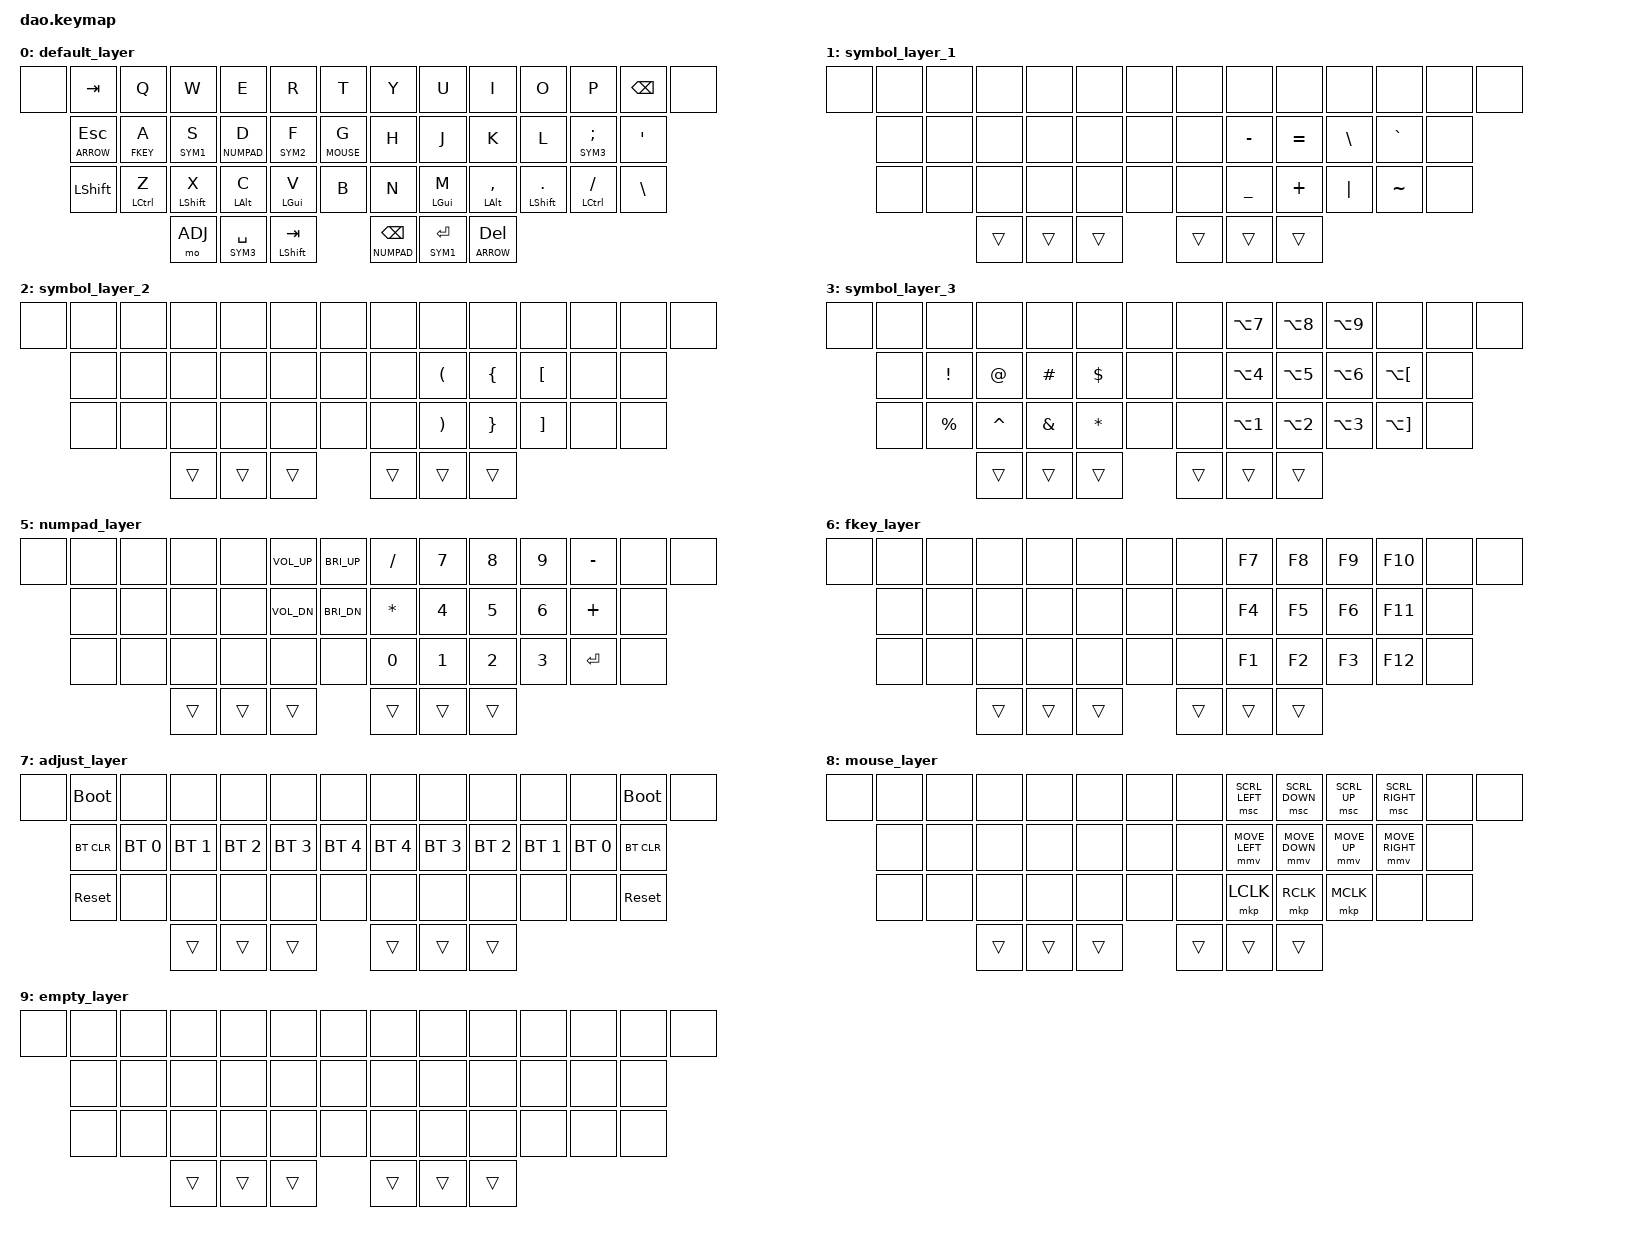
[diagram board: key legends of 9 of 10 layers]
// compile and flash instructions:
// 1. edit this file, push to github,
// 2. download the built files from github actions
// 3. put keyboard into flash mode by double clicking the reset button
// 4. copy them to your keyboard's firmware folder
// note: you have to flash the left one even if you only want to change the right one

/*
 * Copyright (c) 2021 Rafael Yumagulov
 *
 * SPDX-License-Identifier: MIT
 */

#include <behaviors.dtsi>
#include <dt-bindings/zmk/keys.h>
#include <dt-bindings/zmk/bt.h>
#include <dt-bindings/zmk/pointing.h>

// change mouse sensitivity
// #define ZMK_POINTING_DEFAULT_MOVE_VAL 1500  // default: 600
// #define ZMK_POINTING_DEFAULT_SCRL_VAL 20    // default: 10

#define DEF    0
#define SYM1   1
#define SYM2   2
#define SYM3   3
#define ARROW  4
#define NUMPAD 5
#define FKEY   6
#define ADJ    7
#define MOUSE  8

&lt { quick_tap_ms = <200>; };
&mt { quick_tap_ms = <200>; };

/ {
    chosen {
        // zmk,matrix_transform = &default_transform;
        zmk,matrix_transform = &extra_keys_transform;
    };
};

/ {
        behaviors {
                hm: homerow_mods {
                        compatible = "zmk,behavior-hold-tap";
                        label = "HOMEROW_MODS";
                        #binding-cells = <2>;
                        tapping-term-ms = <200>;
                        quick-tap-ms = <200>;
                        flavor = "tap-preferred";
                        bindings = <&kp>, <&kp>;
                };
        };

        keymap {
                compatible = "zmk,keymap";

                default_layer {
                        bindings = <
  &none   &kp TAB           &kp Q         &kp W          &kp E              &kp R                  &kp T         &kp Y                &kp U                 &kp I              &kp O            &kp P            &kp BSPC        &none
          &lt ARROW ESC     &lt FKEY A    &lt SYM1 S     &lt NUMPAD D       &lt SYM2 F             &lt MOUSE G   &kp H                &kp J                 &kp K              &kp L            &lt SYM3 SEMI    &kp SQT
          &kp LSHIFT        &hm LCTRL Z   &hm LSHIFT X   &hm LALT C         &hm LGUI V             &kp B         &kp N                &hm LGUI M            &hm LALT COMMA     &hm LSHIFT DOT   &hm LCTRL FSLH   &kp BSLH
                                          &mo ADJ        &lt SYM3 SPACE     &mt LSHIFT TAB                       &lt NUMPAD BSPC      &lt SYM1 RET          &lt ARROW DEL
                        >;
                };
                symbol_layer_1 {
                        bindings = <
  &none   &none        &none          &none          &none          &none          &none          &none          &none          &none          &none          &none          &none   &none
          &none        &none          &none          &none          &none          &none          &none          &kp MINUS      &kp EQUAL      &kp BSLH       &kp GRAVE      &none
          &none        &none          &none          &none          &none          &none          &none          &kp UNDER      &kp PLUS       &kp PIPE       &kp TILDE      &none
                                                     &trans         &trans         &trans         &trans         &trans         &trans
                        >;
                };
                symbol_layer_2 {
                        bindings = <
  &none   &none        &none          &none          &none          &none          &none          &none          &none          &none          &none          &none          &none   &none
          &none        &none          &none          &none          &none          &none          &none          &kp LPAR       &kp LBRC       &kp LBKT       &none          &none
          &none        &none          &none          &none          &none          &none          &none          &kp RPAR       &kp RBRC       &kp RBKT       &none          &none
                                                     &trans         &trans         &trans         &trans         &trans         &trans
                        >;
                };
                symbol_layer_3 {
                        bindings = <
  &none   &none        &none          &none          &none          &none          &none          &none          &kp LA(N7)      &kp LA(N8)      &kp LA(N9)      &none          &none   &none
          &none        &kp EXCL       &kp AT         &kp HASH       &kp DLLR       &none          &none          &kp LA(N4)      &kp LA(N5)      &kp LA(N6)      &kp LA(LBKT)   &none
          &none        &kp PRCNT      &kp CARET      &kp AMPS       &kp STAR       &none          &none          &kp LA(N1)      &kp LA(N2)      &kp LA(N3)      &kp LA(RBKT)   &none
                                                     &trans         &trans         &trans         &trans         &trans         &trans
                        >;
                };
                arrow_layer {
                        bindings = <
  &none   &none        &none          &none          &kp LC(LS(TAB)) &kp LC(TAB)    &none          &none          &kp BSPC       &kp DEL        &none          &kp PG_UP      &kp HOME   &none
          &none        &none          &kp LA(LEFT)   &kp LA(RIGHT)   &none          &none          &kp LEFT       &kp DOWN       &kp UP         &kp RIGHT      &kp PG_DN      &kp END
          &none        &none          &kp LG(LBKT)   &kp LG(RBKT)    &none          &none          &none          &none          &none          &none          &none          &none          &none
                                                     &trans          &trans         &trans         &trans         &trans         &trans
                        >;
                };
                numpad_layer {
                        bindings = <
  &none   &none        &none          &none          &none          &kp C_VOL_UP   &kp C_BRI_UP   &kp SLASH      &kp N7         &kp N8         &kp N9        &kp MINUS      &none   &none
          &none        &none          &none          &none          &kp C_VOL_DN   &kp C_BRI_DN   &kp STAR       &kp N4         &kp N5         &kp N6        &kp PLUS       &none
          &none        &none          &none          &none          &none          &none          &kp N0         &kp N1         &kp N2         &kp N3        &kp RET        &none
                                                     &trans         &trans         &trans         &trans         &trans         &trans
                        >;
                };
                fkey_layer {
                        bindings = <
  &none   &none        &none          &none          &none          &none          &none          &none          &kp F7         &kp F8         &kp F9         &kp F10       &none   &none
          &none        &none          &none          &none          &none          &none          &none          &kp F4         &kp F5         &kp F6         &kp F11       &none
          &none        &none          &none          &none          &none          &none          &none          &kp F1         &kp F2         &kp F3         &kp F12       &none
                                                     &trans         &trans         &trans         &trans         &trans         &trans
                        >;
                };
                adjust_layer {
                        bindings = <
  &none   &bootloader   &none          &none          &none          &none          &none          &none          &none          &none          &none          &none          &bootloader   &none
          &bt BT_CLR    &bt BT_SEL 0   &bt BT_SEL 1   &bt BT_SEL 2   &bt BT_SEL 3   &bt BT_SEL 4   &bt BT_SEL 4   &bt BT_SEL 3   &bt BT_SEL 2   &bt BT_SEL 1   &bt BT_SEL 0   &bt BT_CLR
          &sys_reset    &none          &none          &none          &none          &none          &none          &none          &none          &none          &none          &sys_reset
                                                      &trans         &trans         &trans         &trans         &trans         &trans
                        >;
                };
                mouse_layer {
                        bindings = <
  &none   &none        &none          &none          &none          &none          &none          &none          &msc SCRL_LEFT &msc SCRL_DOWN &msc SCRL_UP   &msc SCRL_RIGHT &none   &none
          &none        &none          &none          &none          &none          &none          &none          &mmv MOVE_LEFT &mmv MOVE_DOWN &mmv MOVE_UP   &mmv MOVE_RIGHT &none
          &none        &none          &none          &none          &none          &none          &none          &mkp LCLK      &mkp RCLK      &mkp MCLK      &none           &none
                                                     &trans         &trans         &trans         &trans         &trans         &trans
                        >;
                };
                empty_layer {
                        bindings = <
  &none   &none        &none          &none          &none          &none          &none          &none          &none          &none          &none          &none          &none   &none
          &none        &none          &none          &none          &none          &none          &none          &none          &none          &none          &none          &none
          &none        &none          &none          &none          &none          &none          &none          &none          &none          &none          &none          &none
                                                     &trans         &trans         &trans         &trans         &trans         &trans
                        >;
                };
        };
};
